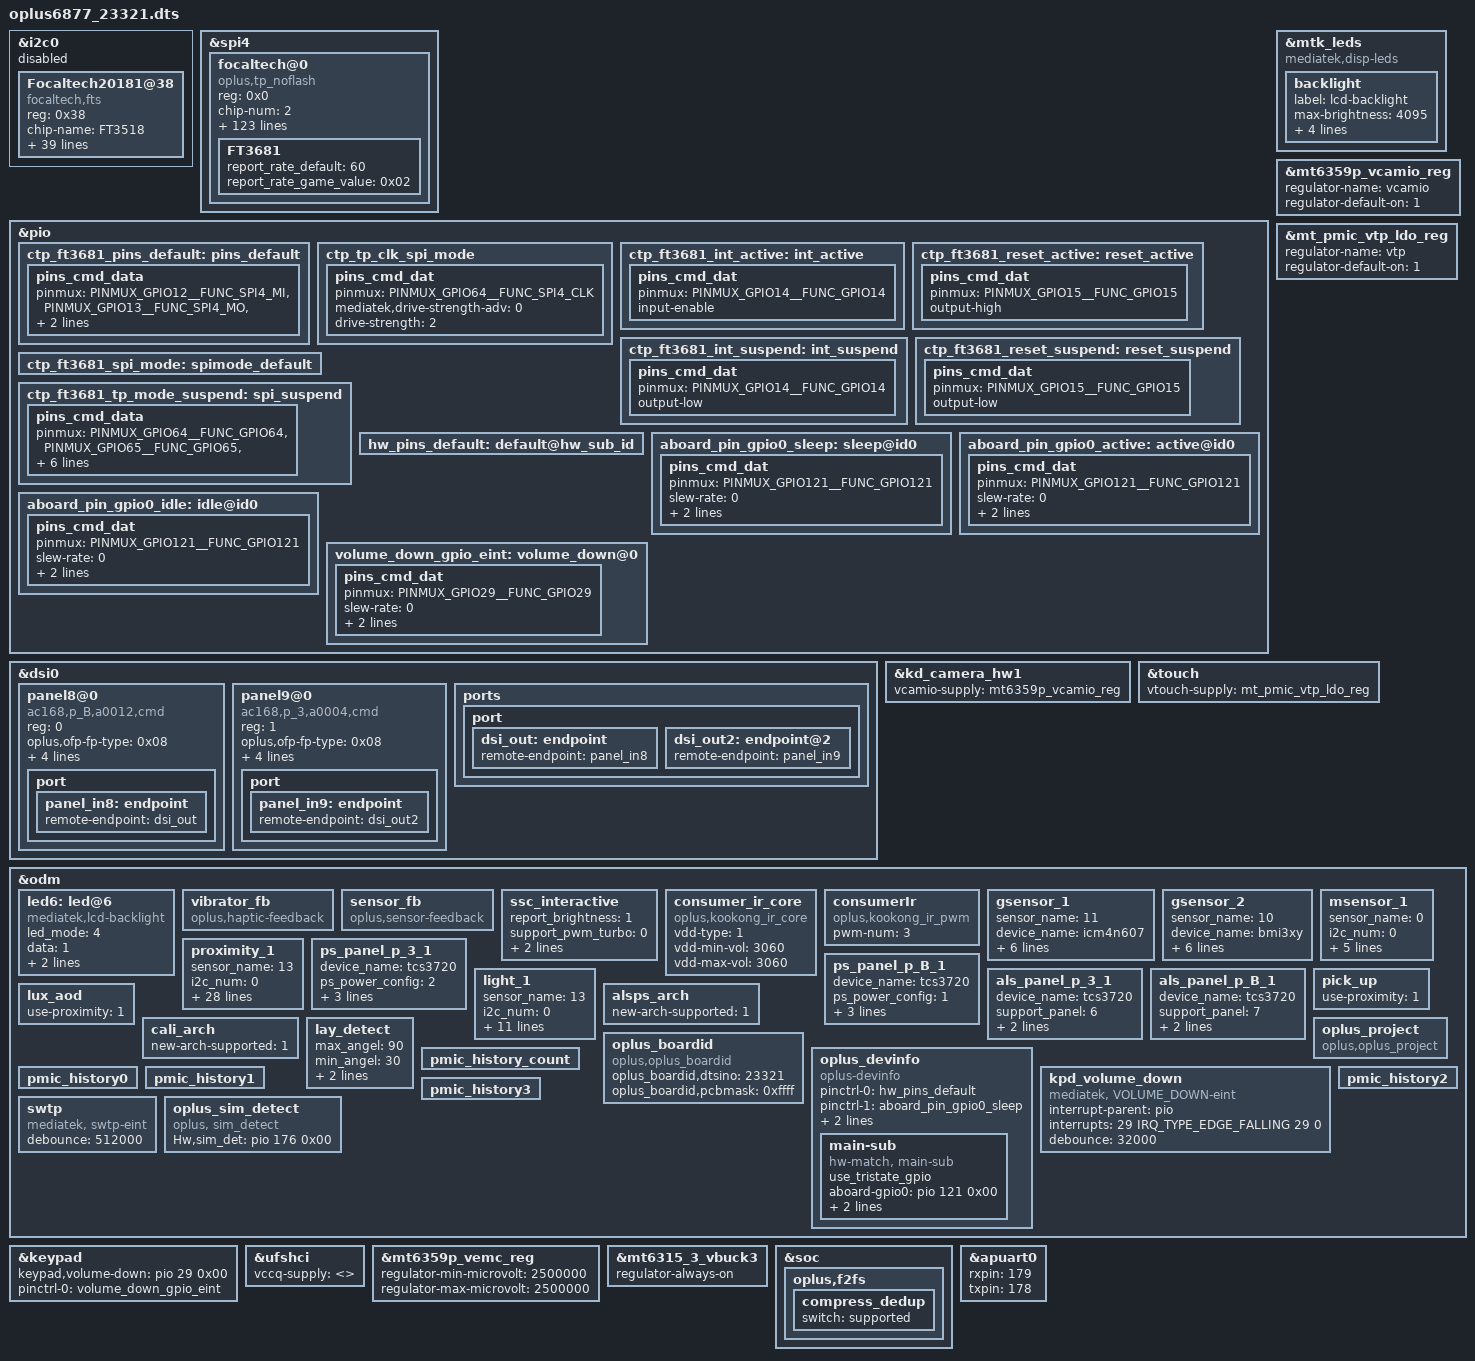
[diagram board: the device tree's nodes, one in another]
// SPDX-License-Identifier: (GPL-2.0 OR MIT)
/*
 * Copyright (C) 2022 MediaTek Inc.
 */
#include "k6877v1_64.dts"

/* #ifdef CONFIG_UFF_FINGERPRINT */
#include "mediatek/oplus_uff_23035.dtsi"
/* #endif CONFIG_UFF_FINGERPRINT */

/*touch start*/

&i2c0 {
	status = "disable";
		Focaltech20181@38 {
		compatible = "focaltech,fts";
		reg = <0x38>;
		chip-name = "FT3518";

		/* Interrupt && Irq-gpio */
		interrupt-parent = <&pio>;
		interrupts = <14 0x2002>;

		/* Power Config */
		vdd_2v8-supply  = <&mt_pmic_vtp_ldo_reg>;
		vdd_2v8_volt = <3000000>;

		/* Other HW Resource */
		irq-gpio = <&pio 14 0x2002>;
		reset-gpio = <&pio 15 0x1>;
		//pinctrl-names = "default";
		//pinctrl-0 = <&ctp_ts_int_active &ctp_ts_reset_active>;

		vid_len = <2>;
		tp_type = <8>;
		// type of tp_dev ,TP-SAMSUNG = 8;
		platform_support_project = <23231>;
		platform_support_project_dir = <23231>;
		platform_support_project_commandline = "default_commandline", "default_commandline", "default_commandline";

		touchpanel,max-num-support = <10>;
		touchpanel,tx-rx-num = <16 34>;
		touchpanel,panel-coords = <4320 9600>;
		touchpanel,display-coords = <1080 2400>;
		touchpanel,touchmajor-limit = <0 216>;
		touchpanel,report-rate = <120 180>;
		touchpanel,smooth-level = <255 2 15 25 45 60>;
		touchpanel,smooth-level-charging = <255 15 20 25 45 60>;
		touchpanel,sensitive-level = <255 20 16 13 10 5>;
		touchpanel,single-optimized-time = <8>;

		//prevention,dead_area_width = <20 20>;
		//prevention,condition_area_width = <60 60 160 160>;
		//prevention,eli_area_width = <240 1000 1200 240>;

		/* SW Support Feature Control */
		black_gesture_support;
		//black_gesture_indep_support;
		fw_edge_limit_support;
		pressure_report_support;
		charger_pump_support;
		game_switch_support;
		smart_gesture_support;
		fw_update_app_support;
		fingerprint_underscreen_support;
		headset_pump_support;
		//irq_need_dev_resume_ok;
		health_monitor_v2_support;
		high_resolution_support;
		//esd_handle_support;
		lcd_tp_refresh_support;
		exception_upload_support;
		/*
		 *Virtual Key Config:
		 *1:touchpanel,button-type: <virtualkey_type  supportted_button-map>
		 *virtualkey_type:
		 *Type 1: using board_properties
		 *Type 2: using same IC (button zone&& touch zone are seprate)
		 *Type 3: using diffrent IC (button zone&& touch zone are seprate)
		 *Type 4: No need of virtual key process
		 *supportted_button-map:select|menu|home|back
		 *
		 *2:touchpanel,button-map
		 *type (X1,Y1)(X2,Y2)(X3,Y3)(Width_X,Hight_Y)--Only when button-type is 0
		 */
		touchpanel,button-type = <4>;
		touchpanel.button-TRx = <0 0>;
	};
};

&spi4 {
 	status = "okay";
 	#address-cells = <1>;
 	#size-cells = <0>;

 	focaltech@0{
 		compatible = "oplus,tp_noflash";
 		reg = <0x0>;
		chip-num = <2>;
 		chip-name = "FT3681","FT3681";
 		status = "okay";
 		spi-max-frequency = <12000000>;
		/* Interrupt && Irq-gpio */
 		interrupt-parent = <&pio>;
 		interrupts = <14 0x2002>;

 		/* Power Config */

 		vdd_2v8-supply  = <&mt_pmic_vtp_ldo_reg>;
 		vdd_2v8_volt = <3000000>;
 		vcc_1v8-supply  = <&mt_pmic_vfp_ldo_reg>;
 		vcc_1v8_volt = <1800000>;


		/* Other HW Resource */

 		irq-gpio = <&pio 14 0x2002>;
 		reset-gpio = <&pio 15 0x1>;

		pinctrl-names = "default",  "ft3681_int_active",
                        "ft3681_reset_active", "ft3681_int_suspend",
                        "ft3681_reset_suspend", "ft3681_spi_mode",
                        "ft3681_tp_mode_suspend";
                pinctrl-0 = <&ctp_ft3681_pins_default &ctp_tp_clk_spi_mode>;
                pinctrl-1 = <&ctp_ft3681_int_active>;
                pinctrl-2 = <&ctp_ft3681_reset_active>;
                pinctrl-3 = <&ctp_ft3681_int_suspend>;
                pinctrl-4 = <&ctp_ft3681_reset_suspend>;
                pinctrl-5 = <&ctp_ft3681_spi_mode>;
                pinctrl-6 = <&ctp_ft3681_tp_mode_suspend>;
 		touchpanel,max-num-support = <10>;
 		touchpanel,tx-rx-num = <16 36>;
 		earsense,tx-rx-num = <17 18>;
 		touchpanel,panel-coords = <8640 19296>;
 		touchpanel,display-coords = <1080 2412>;
 		touchpanel,touchmajor-limit = <128 216>;
 		touchpanel,elimination-range = <20 200 200>;
 		//touchpanel,int-mode = <1>; /*0: interrupt and disable, 1:interrupt and not disable*/
 		touchpanel,smooth-level = <0 110 115 120 140 155>;
 		touchpanel,smooth-level-charging = <0 110 115 120 140 155>;
 		touchpanel,sensitive-level = <0 19 16 14 13 10>;
 		touchpanel,tp-index = <0>;
 		touchpanel,high-frame-rate-time = <60>;
 		disable_suspend_irq_handler_support;

 		vid_len = <2>;
		firmware_name = "0xAC16800","0xAC16800";
		panel_type = <18 3>; /* panel-VXN*/


 		platform_support_project = <23035 23321>;
 		platform_support_project_dir = <23035 23035>;
 		platform_support_project_commandline = "ac168_p_B_a0012_cmd_panel","ac168_p_3_a0004_cmd_panel";

 		prevention,curved_screen_V2;
 		prevention,grip_disable_level = <6>;
 		prevention,updelay_time_ms = <30>;
 		prevention,makeup_cnt_weight = <4 1 2 2 2>;
 		prevention,large_corner_range = <960 2400>;
 		prevention,large_corner_judge_condition = <500 300 800 6 6>;
 		prevention,trx_reject_condition = <8 7 7>;
 		prevention,trx_strict_reject_condition = <7 6 6>;
 		prevention,large_judge_time_ms = <500 50 30>;
 		prevention,large_exit_condition = <15 12 2>;
 		prevention,single_channel_width = <256 256>;
 		prevention,normal_tap_condition = <10 300>;
 		prevention,long_edge_condition = <230 100 180 80>;
 		prevention,long_strict_edge_condition = <170 80>;
 		prevention,long_fingerhold_condition = <50 6 4 4>;
 		prevention,short_edge_condition = <230 100 180 80>;
 		prevention,short_strict_edge_condition = <160 60>;
 		prevention,large_strict_exit_condition = <5 5>;
 		prevention,top_corner_config = <400 1200 380>;
 		prevention,edge_swipe_config = <240 800>;

 		prevention,curved_screen_V4;
 		prevention,long_eliminate_point_type = <2 8640 6640 210 19296 300 1>;
 		prevention,long_fingerhold_condition2 = <560 1600 0 0>;
 		prevention,top_corner_config2 =<3 80 420 1200 0>;
 		prevention,hor_long_top_corner_config =<240 1600 0 0>;
 		prevention,top_middle_config =<8640 800 800 0>;
 		prevention,corner_eliminate_point_type =<0 960 1600 1>;
 		prevention,finger_hold_differ_size = <1 0 360 300>;
 		prevention,finger_hold_max_rx_exit_distance = <5 350 1700>;
 		prevention,max_rx_exit_distance = <1 5 90 350 1400>;
 		prevention,dynamic_finger_hold_exit_distance = <1 290 1700 390>;

                 //grip v4.2 reclining mode
                 prevention,reclining_mode_support = <1>;
                 prevention,long_eliminate_point_type_recli = <2 8640 6640 210 19296 200 1>;
                 prevention,finger_hold_differ_size_recli = <1 0 360 300>;
                 prevention,finger_hold_max_rx_exit_distance_recli = <5 350 1700>;
                 prevention,max_rx_exit_distance_recli = <1 5 90 350 1400>;
                 prevention,dynamic_finger_hold_exit_distance_recli = <1 290 1700 390>;
                 prevention,edge_sliding_matched_support_recli = <1 200 3 0>;
                 prevention,long_edge_condition_recli = <120 100 150 100>;
 		/* SW Support Feature Control */
 		headset_pump_support;
 		health_monitor_v2_support;
 		black_gesture_support;
 		charger_pump_support;
 		lcd_tp_refresh_support;
 		fw_update_app_support;
 		smart_gesture_support;
 		game_switch_support;
 		report_flow_unlock_support;
 		kernel_grip_support;
 		fingerprint_underscreen_support;
 		pressure_report_support;
 		touchpanel,single-optimized-time = <8>;
 		report_rate_white_list_support;
 		auto_test_force_pass_support;
 		snr_read_support;
 		screenoff_fingerprint_info_support;
 		irq_need_dev_resume_ok;
 		sportify_aod_gesture_support;
 		black_gesture_indep_support;
 		thermal_detect_support;
 		exception_upload_support;
 		tp_data_record_support;
 		palm_to_sleep_support;
		health_monitor_support;

 		/*
 		 *Virtual Key Config:
 		 *1:touchpanel,button-type: <virtualkey_type  supportted_button-map>
 		 *virtualkey_type:
 		 *Type 1: using board_properties
 		 *Type 2: using same IC (button zone&& touch zone are seprate)
 		 *Type 3: using diffrent IC (button zone&& touch zone are seprate)
 		 *Type 4: No need of virtual key process
 		 *supportted_button-map:select|menu|home|back
 		 *
 		 *2:touchpanel,button-map
 		 *type (X1,Y1)(X2,Y2)(X3,Y3)(Width_X,Hight_Y)--Only when button-type is 0
 		 */
 		touchpanel,button-type = <4>;
 		touchpanel.button-TRx = <0 0>;

 		FT3681 {
 			report_rate_default = <60>;
 			report_rate_game_value = <0x02>;
 		};
 	};
 };


 &pio {
 	ctp_ft3681_pins_default: pins_default {
 		pins_cmd_data {
 			pinmux = <PINMUX_GPIO12__FUNC_SPI4_MI>,
 				<PINMUX_GPIO13__FUNC_SPI4_MO>,
 				<PINMUX_GPIO65__FUNC_SPI4_CSB>;
 			drive-strength = <2>;
 		};
 	};
 	ctp_tp_clk_spi_mode:ctp_tp_clk_spi_mode{
 		pins_cmd_dat {
 			pinmux = <PINMUX_GPIO64__FUNC_SPI4_CLK>;
 			mediatek,drive-strength-adv = <0>;/*EH[2:0]*/
 			drive-strength = <2>;
 		};
 	};
 	ctp_ft3681_int_active: int_active {
 		pins_cmd_dat {
 			pinmux = <PINMUX_GPIO14__FUNC_GPIO14>;
 			input-enable;
 		};
 	};
 	ctp_ft3681_reset_active: reset_active {
 		pins_cmd_dat {
 			pinmux = <PINMUX_GPIO15__FUNC_GPIO15>;
 			output-high;
 		};
 	};
 	ctp_ft3681_int_suspend: int_suspend {
 		pins_cmd_dat {
 			pinmux = <PINMUX_GPIO14__FUNC_GPIO14>;
 			output-low;
 		};
 	};
 	ctp_ft3681_reset_suspend: reset_suspend {
 		pins_cmd_dat {
 			pinmux = <PINMUX_GPIO15__FUNC_GPIO15>;
 			output-low;
 		};
 	};
 	ctp_ft3681_spi_mode: spimode_default {
 	};
	ctp_ft3681_tp_mode_suspend: spi_suspend {
                pins_cmd_data {
                        pinmux = <PINMUX_GPIO64__FUNC_GPIO64>,
                                        <PINMUX_GPIO65__FUNC_GPIO65>,
                                        <PINMUX_GPIO12__FUNC_GPIO12>,
                                        <PINMUX_GPIO13__FUNC_GPIO13>,
                                        <PINMUX_GPIO14__FUNC_GPIO14>,
                                        <PINMUX_GPIO15__FUNC_GPIO15>;

                        bias-disable;
                        output-low;

                };
        };
 };



&dsi0 {
	status = "okay";
	#address-cells = <1>;
	#size-cells = <0>;
	panel8@0 {
		compatible = "ac168,p_B,a0012,cmd";
		reg = <0>;
		oplus,ofp-fp-type = <0x08>;
		6_vbuck4-supply = <&mt6315_6_vbuck4>;
		vddr-enable-gpios = <&pio 110 0>;
		ldo3-supply = <&mt_pmic_vmc_ldo_reg>;
		reset-gpios = <&pio 40 0>;
		pinctrl-names = "default";
		port {
			panel_in8: endpoint {
				remote-endpoint = <&dsi_out>;
			};
		};
	};
	panel9@0 {
		compatible = "ac168,p_3,a0004,cmd";
		reg = <1>;
		oplus,ofp-fp-type = <0x08>;
		6_vbuck4-supply = <&mt6315_6_vbuck4>;
		vddr-enable-gpios = <&pio 110 0>;
		ldo3-supply = <&mt_pmic_vmc_ldo_reg>;
		reset-gpios = <&pio 40 0>;
		pinctrl-names = "default";
		port {
			panel_in9: endpoint {
				remote-endpoint = <&dsi_out2>;
			};
		};
	};
	ports {
		port {
			dsi_out: endpoint {
				remote-endpoint = <&panel_in8>;
			};
			dsi_out2: endpoint@2 {
				remote-endpoint = <&panel_in9>;
			};
		};
	};
};

&mtk_leds {
	compatible = "mediatek,disp-leds";
	backlight {
		label = "lcd-backlight";
		max-brightness = <4095>;
		max-hw-brightness = <4095>;
		led-bits = <12>;
		trans-bits = <12>;
		default-state = "on";
	};
};

&mt6359p_vcamio_reg {
	regulator-name = "vcamio";
	regulator-default-on = <1>; /* 0:skip, 1: off, 2:on */
	status = "okay";
};
&mt_pmic_vtp_ldo_reg {
	regulator-name = "vtp";
	regulator-default-on = <1>; /* 0:skip, 1: off, 2:on */
	status = "okay";
};

&kd_camera_hw1 {
	vcamio-supply = <&mt6359p_vcamio_reg>;
	status = "okay";
};

&touch {
	vtouch-supply = <&mt_pmic_vtp_ldo_reg>;
	status = "okay";
};

&odm {
/*
	/delete-node/ led@6;
*/

	led6:led@6 {
		compatible = "mediatek,lcd-backlight";
		led_mode = <4>;
		data = <1>;
		led_config = <8 11>;
		pwm_config = <0 1 0 0 0>;
	};

	vibrator_fb:vibrator_fb {
		compatible = "oplus,haptic-feedback";
	};
/* sensor start */
	sensor_fb: sensor_fb {
		compatible = "oplus,sensor-feedback";
	};

	ssc_interactive: ssc_interactive {
		report_brightness = <1>;
		support_pwm_turbo = <0>;
		support_bri_to_scp = <0>;
		need_to_sync_lcd_rate = <0>;
	};

	consumer_ir_core: consumer_ir_core {
		compatible = "oplus,kookong_ir_core";
		status = "okay";
		vdd-type = <1>;
		vdd-min-vol = <3060>;
		vdd-max-vol = <3060>;
	};
	consumerIr: consumerIr {
		compatible = "oplus,kookong_ir_pwm";
		status = "okay";
		pwm-num = <3>;
	};
	/*
	enum {
		LIS3DH,
		LSM6DS3,
		BMI160,
		LIS2HH12,
		LSM6DSM,
		BMI2XY,
		LSM6DSO,
		BMA4XY,
		SC7A20,
		ICM4X6XX,
	};
	*/
	gsensor_1: gsensor_1 {
		status = "okay";
		sensor_name = <11>;//ICM42607
		device_name = "icm4n607";
		i2c_num = <2>;
		i2c_addr = <0>;
		direction = <5>;
		eint_num = <1>;
		gyro_cali_version= <2>;
 		acc_cali_range= <300 300 300>; //300mg
	};
	gsensor_2: gsensor_2 {
		status = "okay";
		sensor_name = <10>;//BMI3XY
		device_name = "bmi3xy";
		i2c_num = <2>;
		i2c_addr = <0>;
		direction = <6>;
		eint_num = <1>;
		gyro_cali_version= <2>;
		acc_cali_range= <300 300 300>; //300mg
	};
	/*
	enum {
		AKM09911,
		MMC3530,
		MMC5603,
		MXG4300,
	};
	*/
	msensor_1: msensor_1 {
		status = "okay";
		sensor_name = <0>;//AKM09911
		i2c_num = <0>;
		i2c_addr = <0x0E>;
		direction = <3>;
		eint_num = <0>;
		soft-mag-parameter = <9176 0 199 1 26 1 70 1 9962 0 9 0 58 0 152 0 10760 0>;
	};
	/*
	enum {
		TMD2725,
		APSD9922,
		STK3335,
		STK3331,
		STK2232,
		TCS3701,
		STK32600,
	};
	*/
	proximity_1: proximity_1 {
		status = "okay";
		sensor_name = <13>;//TCS3720
		i2c_num = <0>;
		i2c_addr = <0x39>;
		direction = <4>;
		eint_num = <2>;
		low_step = <200>;
		high_step = <300>;
		low_limit = <350>;
		high_limit = <450>;
		dirty_low_step = <180>;
		dirty_high_step = <250>;
		ps_dirty_limit = <1023>;
		ps_ir_limit = <500>;
		ps_adjust_min = <0>;
		ps_adjust_max = <600>;
		sampling_count = <5>;
		step_max = <400>;
		step_min = <110>;
		step_div = <1500>;
		anti_shake_delta = <80>;
		dynamic_cali_max = <1024>;
		raw2offset_radio = <20800>;
		offset_max = <250>;
		offset_range_min = <255>;
		offset_range_max = <255>;
		force_cali_limit = <0>;
		cali_jitter_limit = <30>;
		cal_offset_margin = <120>;
		ps_check_num = <3>;
		dmc_flt_thr = <100>;
	};
	ps_panel_p_3_1: ps_panel_p_3_1 {
		status = "okay";
		device_name = "tcs3720";
		ps_power_config = <2>;
		60hz_psd_us = <7500>;
		90hz_psd_us = <1000>;
		120hz_psd_us = <7500>;
	};
	ps_panel_p_B_1: ps_panel_p_B_1 {
		status = "okay";
		device_name = "tcs3720";
		ps_power_config = <1>;
		60hz_psd_us = <5700>;
		90hz_psd_us = <5700>;
		120hz_psd_us = <5700>;
	};
	light_1: light_1 {
		status = "okay";
		sensor_name = <13>; // TCS3720
		i2c_num = <0>;
		i2c_addr = <0x39>;
		direction = <4>;
		eint_num = <2>;
		als_ratio = <110>;
		als_buffer_length = <10>;
		cct_type = <0x02>;  // 0x01 CCT_NORMAL 0x02 CCT_WISE
		device_name = "tcs3720";
		gold_cct_3k = <2016 986 530 3277 1001 1001>;
		gold_cct_6k = <1319 1070 666 2862 1001 1001>;
		gold_cct_factor = <941 946 924 966 1001 1001>;
		need_gain_cali = <1>;
	};
	als_panel_p_3_1: als_panel_p_3_1 {
		status = "okay";
		device_name = "tcs3720";
		support_panel = <6>;
		gold_cct_3k = <2033 981 499 3223 1001 1001>;
		gold_cct_6k = <1344 1068 640 2836 1001 1001>;
	};
	als_panel_p_B_1: als_panel_p_B_1 {
		status = "okay";
		device_name = "tcs3720";
		support_panel = <7>;
		gold_cct_3k = <2016 986 530 3277 1001 1001>;
		gold_cct_6k = <1319 1070 666 2862 1001 1001>;
	};

	pick_up: pick_up {
		status = "okay";
		use-proximity = <1>;
	};
	lux_aod: lux_aod {
		status = "okay";
		use-proximity = <1>;
	};
	alsps_arch: alsps_arch {
		status = "okay";
		new-arch-supported = <1>;
	};
	cali_arch: cali_arch {
		status = "okay";
		new-arch-supported = <1>;
	};
	lay_detect: lay_detect{
		status = "okay";
		max_angel = <90>;
		min_angel = <30>;
		lay_in_time = <10>;
		lay_out_time = <3>;
	};
/* sensor end */

	oplus_boardid:oplus_boardid {
		compatible = "oplus,oplus_boardid";
		oplus_boardid,dtsino="23321";//only one u32
		oplus_boardid,pcbmask="0xffff";//all mask 0xffff
	};

/* OPLUS_BUG_STABILITY oplus project start */
	oplus_project:oplus_project {
		compatible = "oplus,oplus_project";
	};
	oplus_devinfo:oplus_devinfo {
		compatible = "oplus-devinfo";

		pinctrl-names = "default", "aboard_gpio0_sleep", "aboard_gpio0_active", "aboard_gpio0_idle";
		pinctrl-0 = <&hw_pins_default>;
		pinctrl-1 = <&aboard_pin_gpio0_sleep>;
		pinctrl-2 = <&aboard_pin_gpio0_active>;
		pinctrl-3 = <&aboard_pin_gpio0_idle>;
		main-sub {
			use_tristate_gpio;
			compatible = "hw-match, main-sub";
			aboard-gpio0 = <&pio 121 0x00>;
			aboard-patterns = <0 0>;
			/*main board*/
			match-projects = <23035 23321>;

		};
	};

/* OPLUS_BUG_STABILITY oplus project end */

	kpd_volume_down:kpd_volume_down {
		compatible = "mediatek, VOLUME_DOWN-eint";
		interrupt-parent = <&pio>;
		interrupts = <29 IRQ_TYPE_EDGE_FALLING 29 0>;/*TRQ num 29 is linked with gpio29 (mt6877)*/
		debounce = <32000>;
		status = "okay";
	};

	pmic_history_count:pmic_history_count {
	};
	pmic_history0:pmic_history0 {
	};
	pmic_history1:pmic_history1 {
	};
	pmic_history2:pmic_history2 {
	};
	pmic_history3:pmic_history3 {
	};
	//#ifdef OPLUS_VENDOR_SWTP
	swtp: swtp {
		compatible = "mediatek, swtp-eint";
		debounce = <512000>;
	};
	//#endif  /*OPLUS_VENDOR_SWTP*/

};

&odm {
/* Add for sim detect */
    oplus_sim_detect {
        compatible = "oplus, sim_detect";
        Hw,sim_det = <&pio 176 0x00>;
    };
};

&pio {
        hw_pins_default:default@hw_sub_id {
        };

        aboard_pin_gpio0_sleep:sleep@id0 {
                pins_cmd_dat {
                        pinmux = <PINMUX_GPIO121__FUNC_GPIO121>;
                        slew-rate = <0>;
                        bias-pull-down;
                        input-enable;
                };
        };

        aboard_pin_gpio0_active:active@id0 {
                pins_cmd_dat {
                        pinmux = <PINMUX_GPIO121__FUNC_GPIO121>;
                        slew-rate = <0>;
                        bias-pull-up;
                        input-enable;
                };
        };

        aboard_pin_gpio0_idle:idle@id0 {
                pins_cmd_dat {
                        pinmux = <PINMUX_GPIO121__FUNC_GPIO121>;
                        slew-rate = <0>;
                        bias-disable;
                        input-enable;
                };
        };
};

&keypad {
        keypad,volume-down = <&pio 29 0x00>;
        pinctrl-names = "volume_down_as_int";
        pinctrl-0 = <&volume_down_gpio_eint>;
        status = "okay";
};

&pio {
        volume_down_gpio_eint:volume_down@0{
                pins_cmd_dat {
                        pinmux = <PINMUX_GPIO29__FUNC_GPIO29>;
                        slew-rate = <0>;  /*direction 0:in, 1:out*/
                        input-enable;
			bias-disable;
                };
        };
};

&ufshci {
    vccq-supply = <>;
};

&mt6359p_vemc_reg {
	regulator-min-microvolt = <2500000>;
	regulator-max-microvolt = <2500000>;
};

&mt6315_3_vbuck3 {
	regulator-always-on;
};

&soc {
    oplus,f2fs {
        compress_dedup {
            switch = "supported";
        };
    };
};

#include "oplus6877_23321/cust.dtsi"
#include "mediatek/oplus_chg/cust_mt6877_oplus_charge_23321.dtsi"
&apuart0 {
	rxpin = <179>;
	txpin = <178>;
};

#include "mediatek/cust_mt6877_camera_23035.dtsi"
#include "mediatek/oplus6877_audio_avatar_h.dtsi"
/*End of this file, DO NOT ADD ANYTHING HERE*/


